# CC2756 register map
File version: 1.0
CPU: CM4 r0p4, little endian, no MPU, no FPU, VTOR, 3 interrupt priority bits
Registers are 32-bit, read-write, reset 0x0 unless marked. A register's access mark holds for its fields unless they carry their own. Offsets are from the block's base; [hi:lo] are bit positions; {n}, {i} and the like mark numbered series; 'fields as' and 'values as' point back to an identical list.

## LRFDRFE32 (part 1 of 2)
Base 0x40083400
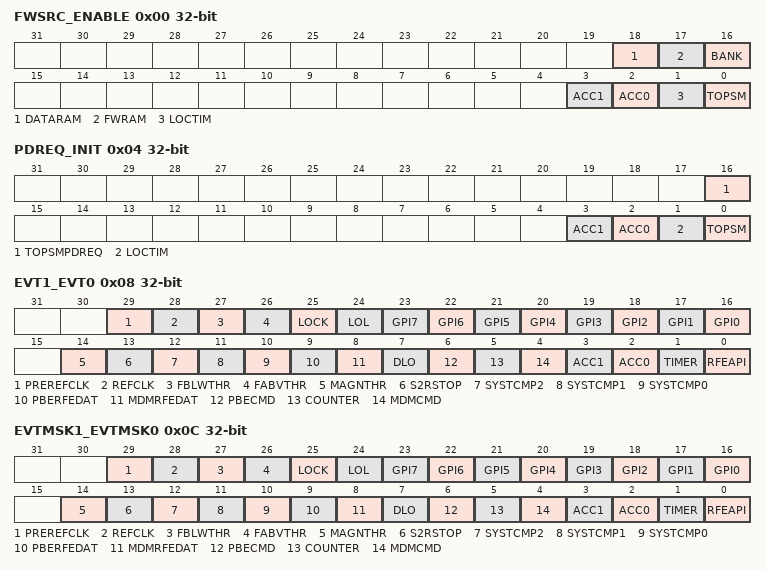
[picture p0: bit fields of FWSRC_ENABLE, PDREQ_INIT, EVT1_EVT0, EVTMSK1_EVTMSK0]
0x00 FWSRC_ENABLE — Internal. Only to be used through TI provided API.
  [18] DATARAM — Internal. Only to be used through TI provided API.
    1=S2RRAM (Internal. Only to be used through TI provided API.); 0=RFERAM (Internal. Only to be used through TI provided API.)
  [17] FWRAM — Internal. Only to be used through TI provided API.
    values as DATARAM
  [16] BANK — Internal. Only to be used through TI provided API.
    1=ONE (Internal. Only to be used through TI provided API.); 0=ZERO (Internal. Only to be used through TI provided API.)
  [3] ACC1 — Internal. Only to be used through TI provided API.
    1=EN (Internal. Only to be used through TI provided API.); 0=DIS (Internal. Only to be used through TI provided API.)
  [2] ACC0 — Internal. Only to be used through TI provided API.
    values as ACC1
  [1] LOCTIM — Internal. Only to be used through TI provided API.
    values as ACC1
  [0] TOPSM — Internal. Only to be used through TI provided API.
    values as ACC1
0x04 PDREQ_INIT wo — Internal. Only to be used through TI provided API.
  [16] TOPSMPDREQ — Internal. Only to be used through TI provided API.
    values as FWSRC_ENABLE.BANK
  [3] ACC1 — Internal. Only to be used through TI provided API.
    1=RESET (Internal. Only to be used through TI provided API.); 0=NO_EFFECT (Internal. Only to be used through TI provided API.)
  [2] ACC0 — Internal. Only to be used through TI provided API.
    values as ACC1
  [1] LOCTIM — Internal. Only to be used through TI provided API.
    values as ACC1
  [0] TOPSM — Internal. Only to be used through TI provided API.
    values as ACC1
0x08 EVT1_EVT0 ro — Internal. Only to be used through TI provided API.
  [all] fields
    values as FWSRC_ENABLE.BANK
  [29] PREREFCLK — Internal. Only to be used through TI provided API.
  [28] REFCLK — Internal. Only to be used through TI provided API.
  [27] FBLWTHR — Internal. Only to be used through TI provided API.
  [26] FABVTHR — Internal. Only to be used through TI provided API.
  [25] LOCK — Internal. Only to be used through TI provided API.
  [24] LOL — Internal. Only to be used through TI provided API.
  [n+16] GPI{n} (n=0..7) — Internal. Only to be used through TI provided API.
  [14] MAGNTHR — Internal. Only to be used through TI provided API.
  [13] S2RSTOP — Internal. Only to be used through TI provided API.
  [12] SYSTCMP2 — Internal. Only to be used through TI provided API.
  [11] SYSTCMP1 — Internal. Only to be used through TI provided API.
  [10] SYSTCMP0 — Internal. Only to be used through TI provided API.
  [9] PBERFEDAT — Internal. Only to be used through TI provided API.
  [8] MDMRFEDAT — Internal. Only to be used through TI provided API.
  [7] DLO — Internal. Only to be used through TI provided API.
  [6] PBECMD — Internal. Only to be used through TI provided API.
  [5] COUNTER — Internal. Only to be used through TI provided API.
  [4] MDMCMD — Internal. Only to be used through TI provided API.
  [3] ACC1 — Internal. Only to be used through TI provided API.
  [2] ACC0 — Internal. Only to be used through TI provided API.
  [1] TIMER — Internal. Only to be used through TI provided API.
  [0] RFEAPI — Internal. Only to be used through TI provided API.
0x0C EVTMSK1_EVTMSK0 — Internal. Only to be used through TI provided API.
  [all] fields
    values as FWSRC_ENABLE.ACC1
  [29] PREREFCLK — Internal. Only to be used through TI provided API.
  [28] REFCLK — Internal. Only to be used through TI provided API.
  [27] FBLWTHR — Internal. Only to be used through TI provided API.
  [26] FABVTHR — Internal. Only to be used through TI provided API.
  [25] LOCK — Internal. Only to be used through TI provided API.
  [24] LOL — Internal. Only to be used through TI provided API.
  [n+16] GPI{n} (n=0..7) — Internal. Only to be used through TI provided API.
  [14] MAGNTHR — Internal. Only to be used through TI provided API.
  [13] S2RSTOP — Internal. Only to be used through TI provided API.
  [12] SYSTCMP2 — Internal. Only to be used through TI provided API.
  [11] SYSTCMP1 — Internal. Only to be used through TI provided API.
  [10] SYSTCMP0 — Internal. Only to be used through TI provided API.
  [9] PBERFEDAT — Internal. Only to be used through TI provided API.
  [8] MDMRFEDAT — Internal. Only to be used through TI provided API.
  [7] DLO — Internal. Only to be used through TI provided API.
  [6] PBECMD — Internal. Only to be used through TI provided API.
  [5] COUNTER — Internal. Only to be used through TI provided API.
  [4] MDMCMD — Internal. Only to be used through TI provided API.
  [3] ACC1 — Internal. Only to be used through TI provided API.
  [2] ACC0 — Internal. Only to be used through TI provided API.
  [1] TIMER — Internal. Only to be used through TI provided API.
  [0] RFEAPI — Internal. Only to be used through TI provided API.
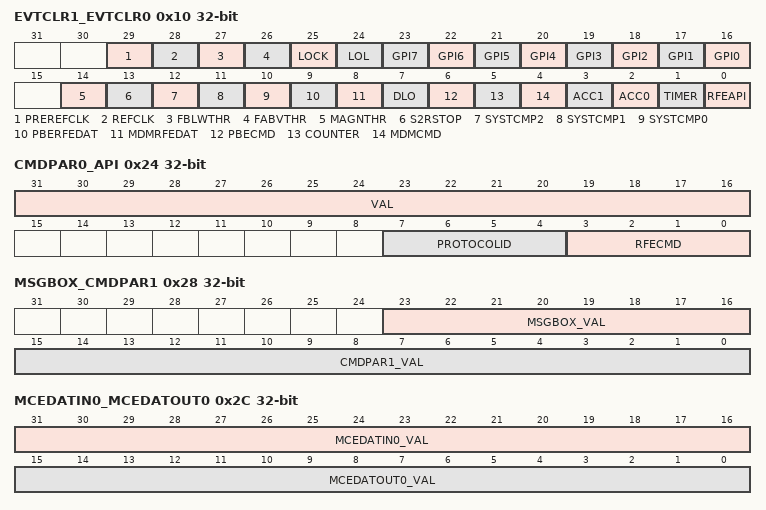
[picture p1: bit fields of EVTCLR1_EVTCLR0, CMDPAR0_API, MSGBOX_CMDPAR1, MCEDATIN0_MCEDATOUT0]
0x10 EVTCLR1_EVTCLR0 wo — Internal. Only to be used through TI provided API.
  fields as EVT1_EVT0
0x14 HFXTSTAT ro — Internal. Only to be used through TI provided API.
  [0] STAT
    1=QUAL (Internal. Only to be used through TI provided API.); 0=NONQUAL (Internal. Only to be used through TI provided API.)
0x18 RFSTATE — Internal. Only to be used through TI provided API.
  [3:0] VAL
    3=RX (Internal. Only to be used through TI provided API.); 2=TX (Internal. Only to be used through TI provided API.); 1=SYNTH (Internal. Only to be used through TI provided API.); 0=IDLE (Internal. Only to be used through TI provided API.)
0x1C SPIN ro reset 0xFF — Internal. Only to be used through TI provided API.
  [7:0] OPT
    255=ALLONES (Internal. Only to be used through TI provided API.); 0=ALLZEROS (Internal. Only to be used through TI provided API.)
0x24 CMDPAR0_API ro — Internal. Only to be used through TI provided API.
  [31:16] VAL — Internal. Only to be used through TI provided API.
    0xFFFF=ALLONES (Internal. Only to be used through TI provided API.); 0=ALLZEROS (Internal. Only to be used through TI provided API.)
  [7:4] PROTOCOLID — Internal. Only to be used through TI provided API.
    15=ALLONES (Internal. Only to be used through TI provided API.); 0=ALLZEROS (Internal. Only to be used through TI provided API.)
  [3:0] RFECMD — Internal. Only to be used through TI provided API.
    values as PROTOCOLID
0x28 MSGBOX_CMDPAR1 ro — Internal. Only to be used through TI provided API.
  [23:16] MSGBOX_VAL — Internal. Only to be used through TI provided API.
    values as SPIN.OPT
  [15:0] CMDPAR1_VAL — Internal. Only to be used through TI provided API.
    values as CMDPAR0_API.VAL
0x2C MCEDATIN0_MCEDATOUT0 — Internal. Only to be used through TI provided API.
  [31:16] MCEDATIN0_VAL ro — Internal. Only to be used through TI provided API.
    values as CMDPAR0_API.VAL
  [15:0] MCEDATOUT0_VAL — Internal. Only to be used through TI provided API.
    values as CMDPAR0_API.VAL
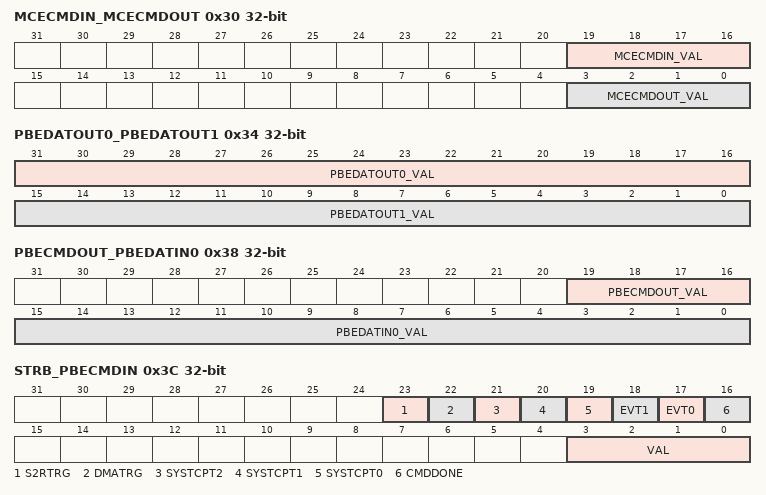
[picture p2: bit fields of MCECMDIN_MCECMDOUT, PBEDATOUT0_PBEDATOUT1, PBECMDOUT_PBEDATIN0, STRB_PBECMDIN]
0x30 MCECMDIN_MCECMDOUT — Internal. Only to be used through TI provided API.
  [19:16] MCECMDIN_VAL ro — Internal. Only to be used through TI provided API.
    values as CMDPAR0_API.PROTOCOLID
  [3:0] MCECMDOUT_VAL — Internal. Only to be used through TI provided API.
    values as CMDPAR0_API.PROTOCOLID
0x34 PBEDATOUT0_PBEDATOUT1 — Internal. Only to be used through TI provided API.
  [31:16] PBEDATOUT0_VAL — Internal. Only to be used through TI provided API.
    values as CMDPAR0_API.VAL
  [15:0] PBEDATOUT1_VAL — Internal. Only to be used through TI provided API.
    values as CMDPAR0_API.VAL
0x38 PBECMDOUT_PBEDATIN0 ro — Internal. Only to be used through TI provided API.
  [19:16] PBECMDOUT_VAL — Internal. Only to be used through TI provided API.
    values as CMDPAR0_API.PROTOCOLID
  [15:0] PBEDATIN0_VAL — Internal. Only to be used through TI provided API.
    values as CMDPAR0_API.VAL
0x3C STRB_PBECMDIN ro — Internal. Only to be used through TI provided API.
  [23] S2RTRG wo — Internal. Only to be used through TI provided API.
    values as FWSRC_ENABLE.BANK
  [22] DMATRG wo — Internal. Only to be used through TI provided API.
    values as FWSRC_ENABLE.BANK
  [21] SYSTCPT2 wo — Internal. Only to be used through TI provided API.
    values as FWSRC_ENABLE.BANK
  [20] SYSTCPT1 wo — Internal. Only to be used through TI provided API.
    values as FWSRC_ENABLE.BANK
  [19] SYSTCPT0 wo — Internal. Only to be used through TI provided API.
    values as FWSRC_ENABLE.BANK
  [18] EVT1 wo — Internal. Only to be used through TI provided API.
    values as FWSRC_ENABLE.BANK
  [17] EVT0 wo — Internal. Only to be used through TI provided API.
    values as FWSRC_ENABLE.BANK
  [16] CMDDONE wo — Internal. Only to be used through TI provided API.
    1=YES (Internal. Only to be used through TI provided API.); 0=NO (Internal. Only to be used through TI provided API.)
  [3:0] VAL — Internal. Only to be used through TI provided API.
    values as CMDPAR0_API.PROTOCOLID
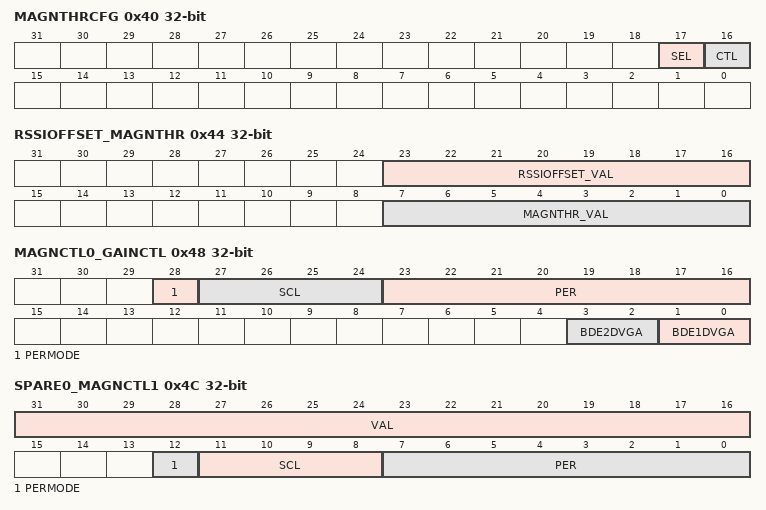
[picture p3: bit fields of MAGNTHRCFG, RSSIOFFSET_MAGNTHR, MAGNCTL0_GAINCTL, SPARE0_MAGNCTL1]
0x40 MAGNTHRCFG — Internal. Only to be used through TI provided API.
  [17] SEL — Internal. Only to be used through TI provided API.
    1=MAGNACC1 (Internal. Only to be used through TI provided API.); 0=MAGNACC0 (Internal. Only to be used through TI provided API.)
  [16] CTL — Internal. Only to be used through TI provided API.
    values as FWSRC_ENABLE.ACC1
0x44 RSSIOFFSET_MAGNTHR — Internal. Only to be used through TI provided API.
  [23:16] RSSIOFFSET_VAL — Internal. Only to be used through TI provided API.
    values as SPIN.OPT
  [7:0] MAGNTHR_VAL — Internal. Only to be used through TI provided API.
    values as SPIN.OPT
0x48 MAGNCTL0_GAINCTL — Internal. Only to be used through TI provided API.
  [28] PERMODE — Internal. Only to be used through TI provided API.
    1=PERIODIC (Internal. Only to be used through TI provided API.); 0=ONESHOT (Internal. Only to be used through TI provided API.)
  [27:24] SCL — Internal. Only to be used through TI provided API.
    8=DIV256 (Internal. Only to be used through TI provided API.); 7=DIV128 (Internal. Only to be used through TI provided API.); 6=DIV64 (Internal. Only to be used through TI provided API.); 5=DIV32 (Internal. Only to be used through TI provided API.); 4=DIV16 (Internal. Only to be used through TI provided API.); 3=DIV8 (Internal. Only to be used through TI provided API.); 2=DIV4 (Internal. Only to be used through TI provided API.); 1=DIV2 (Internal. Only to be used through TI provided API.); 0=DIV1 (Internal. Only to be used through TI provided API.)
  [23:16] PER — Internal. Only to be used through TI provided API.
    values as SPIN.OPT
  [3:2] BDE2DVGA — Internal. Only to be used through TI provided API.
    3=GAIN8 (Internal. Only to be used through TI provided API.); 2=GAIN4 (Internal. Only to be used through TI provided API.); 1=GAIN2 (Internal. Only to be used through TI provided API.); 0=GAIN1 (Internal. Only to be used through TI provided API.)
  [1:0] BDE1DVGA — Internal. Only to be used through TI provided API.
    values as BDE2DVGA
0x4C SPARE0_MAGNCTL1 — Internal. Only to be used through TI provided API.
  [31:16] VAL — Internal. Only to be used through TI provided API.
    values as CMDPAR0_API.VAL
  [12] PERMODE — Internal. Only to be used through TI provided API.
    values as MAGNCTL0_GAINCTL.PERMODE
  [11:8] SCL — Internal. Only to be used through TI provided API.
    values as MAGNCTL0_GAINCTL.SCL
  [7:0] PER — Internal. Only to be used through TI provided API.
    values as SPIN.OPT
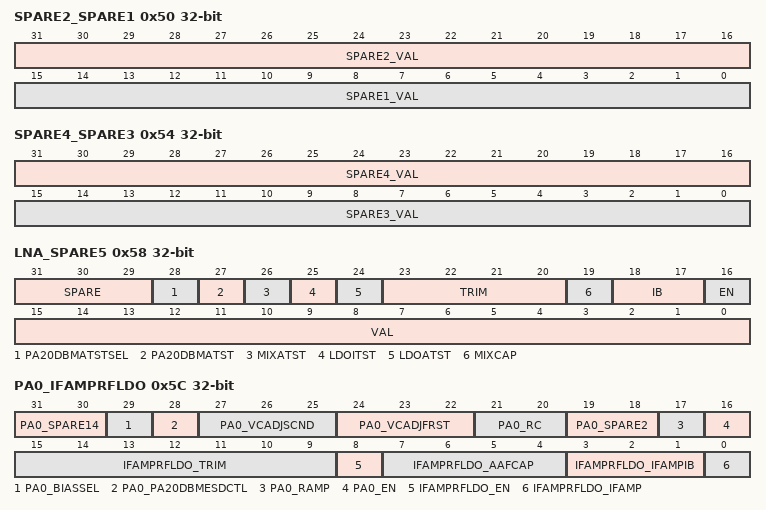
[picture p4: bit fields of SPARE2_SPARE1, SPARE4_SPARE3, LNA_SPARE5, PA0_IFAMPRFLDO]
0x50 SPARE2_SPARE1 — Internal. Only to be used through TI provided API.
  [31:16] SPARE2_VAL — Internal. Only to be used through TI provided API.
    values as CMDPAR0_API.VAL
  [15:0] SPARE1_VAL — Internal. Only to be used through TI provided API.
    values as CMDPAR0_API.VAL
0x54 SPARE4_SPARE3 — Internal. Only to be used through TI provided API.
  [31:16] SPARE4_VAL — Internal. Only to be used through TI provided API.
    values as CMDPAR0_API.VAL
  [15:0] SPARE3_VAL — Internal. Only to be used through TI provided API.
    values as CMDPAR0_API.VAL
0x58 LNA_SPARE5 — Internal. Only to be used through TI provided API.
  [31:29] SPARE — Internal. Only to be used through TI provided API.
    values as FWSRC_ENABLE.ACC1
  [28] PA20DBMATSTSEL — Internal. Only to be used through TI provided API.
    1=SECOND (Internal. Only to be used through TI provided API.); 0=FIRST (Internal. Only to be used through TI provided API.)
  [27] PA20DBMATST — Internal. Only to be used through TI provided API.
    values as FWSRC_ENABLE.ACC1
  [26] MIXATST — Internal. Only to be used through TI provided API.
    values as FWSRC_ENABLE.ACC1
  [25] LDOITST — Internal. Only to be used through TI provided API.
    values as FWSRC_ENABLE.ACC1
  [24] LDOATST — Internal. Only to be used through TI provided API.
    values as FWSRC_ENABLE.ACC1
  [23:20] TRIM — Internal. Only to be used through TI provided API.
    15=ONES (Internal. Only to be used through TI provided API.); 0=ZEROS (Internal. Only to be used through TI provided API.)
  [19] MIXCAP — Internal. Only to be used through TI provided API.
    values as FWSRC_ENABLE.ACC1
  [18:17] IB — Internal. Only to be used through TI provided API.
    3=MAX (Internal. Only to be used through TI provided API.); 0=MIN (Internal. Only to be used through TI provided API.)
  [16] EN — Internal. Only to be used through TI provided API.
    1=ON (Internal. Only to be used through TI provided API.); 0=OFF (Internal. Only to be used through TI provided API.)
  [15:0] VAL — Internal. Only to be used through TI provided API.
    values as CMDPAR0_API.VAL
0x5C PA0_IFAMPRFLDO — Internal. Only to be used through TI provided API.
  [31:30] PA0_SPARE14 — Internal. Only to be used through TI provided API.
    values as LNA_SPARE5.IB
  [29] PA0_BIASSEL — Internal. Only to be used through TI provided API.
    values as FWSRC_ENABLE.BANK
  [28] PA0_PA20DBMESDCTL — Internal. Only to be used through TI provided API.
    values as FWSRC_ENABLE.BANK
  [27:25] PA0_VCADJSCND — Internal. Only to be used through TI provided API.
    7=MAX (Internal. Only to be used through TI provided API.); 0=MIN (Internal. Only to be used through TI provided API.)
  [24:22] PA0_VCADJFRST — Internal. Only to be used through TI provided API.
    values as PA0_VCADJSCND
  [21:20] PA0_RC — Internal. Only to be used through TI provided API.
    values as LNA_SPARE5.IB
  [19:18] PA0_SPARE2 — Internal. Only to be used through TI provided API.
    values as LNA_SPARE5.IB
  [17] PA0_RAMP — Internal. Only to be used through TI provided API.
    1=UP (Internal. Only to be used through TI provided API.); 0=DOWN (Internal. Only to be used through TI provided API.)
  [16] PA0_EN — Internal. Only to be used through TI provided API.
    values as FWSRC_ENABLE.ACC1
  [15:9] IFAMPRFLDO_TRIM — Internal. Only to be used through TI provided API.
    127=BYPASS (Internal. Only to be used through TI provided API.); 126=MAX (Internal. Only to be used through TI provided API.); 0=MIN (Internal. Only to be used through TI provided API.)
  [8] IFAMPRFLDO_EN — Internal. Only to be used through TI provided API.
    values as FWSRC_ENABLE.ACC1
  [7:4] IFAMPRFLDO_AAFCAP — Internal. Only to be used through TI provided API.
    15=MAX (Internal. Only to be used through TI provided API.); 0=MIN (Internal. Only to be used through TI provided API.)
  [3:1] IFAMPRFLDO_IFAMPIB — Internal. Only to be used through TI provided API.
    values as PA0_VCADJSCND
  [0] IFAMPRFLDO_IFAMP — Internal. Only to be used through TI provided API.
    values as FWSRC_ENABLE.ACC1
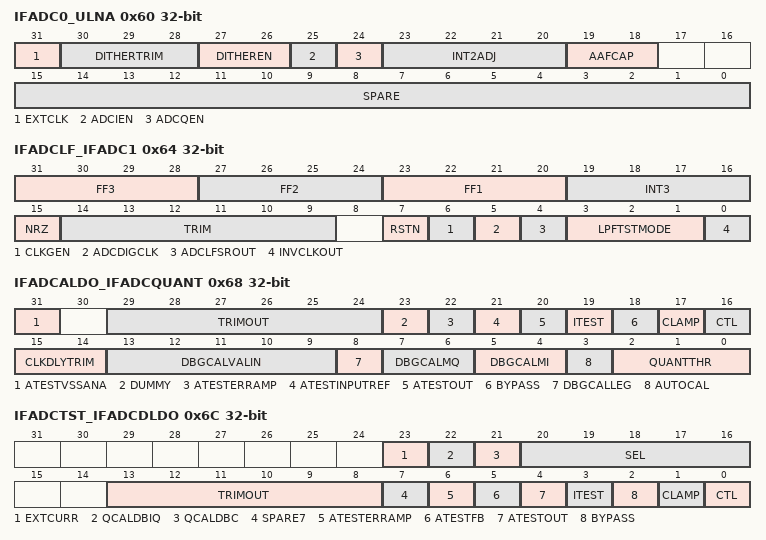
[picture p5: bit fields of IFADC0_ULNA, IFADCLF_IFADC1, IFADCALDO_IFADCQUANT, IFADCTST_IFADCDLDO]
0x60 IFADC0_ULNA — Internal. Only to be used through TI provided API.
  [31] EXTCLK — Internal. Only to be used through TI provided API.
    values as FWSRC_ENABLE.ACC1
  [30:28] DITHERTRIM — Internal. Only to be used through TI provided API.
    7=ONES (Internal. Only to be used through TI provided API.); 0=ZEROS (Internal. Only to be used through TI provided API.)
  [27:26] DITHEREN — Internal. Only to be used through TI provided API.
    3=ENG (Internal. Only to be used through TI provided API.); 2=ENSD (Internal. Only to be used through TI provided API.); 1=ENS (Internal. Only to be used through TI provided API.); 0=DIS (Internal. Only to be used through TI provided API.)
  [25] ADCIEN — Internal. Only to be used through TI provided API.
    values as FWSRC_ENABLE.ACC1
  [24] ADCQEN — Internal. Only to be used through TI provided API.
    values as FWSRC_ENABLE.ACC1
  [23:20] INT2ADJ — Internal. Only to be used through TI provided API.
    values as LNA_SPARE5.TRIM
  [19:18] AAFCAP — Internal. Only to be used through TI provided API.
    values as DITHEREN
  [15:0] SPARE — Internal. Only to be used through TI provided API.
    values as CMDPAR0_API.VAL
0x64 IFADCLF_IFADC1 — Internal. Only to be used through TI provided API.
  [31:28] FF3 — Internal. Only to be used through TI provided API.
    values as LNA_SPARE5.TRIM
  [27:24] FF2 — Internal. Only to be used through TI provided API.
    values as LNA_SPARE5.TRIM
  [23:20] FF1 — Internal. Only to be used through TI provided API.
    values as LNA_SPARE5.TRIM
  [19:16] INT3 — Internal. Only to be used through TI provided API.
    values as LNA_SPARE5.TRIM
  [15] NRZ — Internal. Only to be used through TI provided API.
    values as FWSRC_ENABLE.ACC1
  [14:9] TRIM — Internal. Only to be used through TI provided API.
    63=ONES (Internal. Only to be used through TI provided API.); 0=ZEROS (Internal. Only to be used through TI provided API.)
  [7] RSTN — Internal. Only to be used through TI provided API.
    1=DIS (Internal. Only to be used through TI provided API.); 0=EN (Internal. Only to be used through TI provided API.)
  [6] CLKGEN — Internal. Only to be used through TI provided API.
    values as FWSRC_ENABLE.ACC1
  [5] ADCDIGCLK — Internal. Only to be used through TI provided API.
    values as FWSRC_ENABLE.ACC1
  [4] ADCLFSROUT — Internal. Only to be used through TI provided API.
    values as FWSRC_ENABLE.ACC1
  [3:1] LPFTSTMODE — Internal. Only to be used through TI provided API.
    values as FWSRC_ENABLE.ACC1
  [0] INVCLKOUT — Internal. Only to be used through TI provided API.
    values as FWSRC_ENABLE.ACC1
0x68 IFADCALDO_IFADCQUANT — Internal. Only to be used through TI provided API.
  [31] ATESTVSSANA — Internal. Only to be used through TI provided API.
    values as FWSRC_ENABLE.ACC1
  [29:24] TRIMOUT — Internal. Only to be used through TI provided API.
    values as IFADCLF_IFADC1.TRIM
  [23] DUMMY — Internal. Only to be used through TI provided API.
    1=DISN (Internal. Only to be used through TI provided API.); 0=ENN (Internal. Only to be used through TI provided API.)
  [22] ATESTERRAMP — Internal. Only to be used through TI provided API.
    values as FWSRC_ENABLE.ACC1
  [21] ATESTINPUTREF — Internal. Only to be used through TI provided API.
    values as FWSRC_ENABLE.ACC1
  [20] ATESTOUT — Internal. Only to be used through TI provided API.
    values as FWSRC_ENABLE.ACC1
  [19] ITEST — Internal. Only to be used through TI provided API.
    values as FWSRC_ENABLE.ACC1
  [18] BYPASS — Internal. Only to be used through TI provided API.
    values as FWSRC_ENABLE.ACC1
  [17] CLAMP — Internal. Only to be used through TI provided API.
    values as FWSRC_ENABLE.ACC1
  [16] CTL — Internal. Only to be used through TI provided API.
    values as FWSRC_ENABLE.ACC1
  [15:14] CLKDLYTRIM — Internal. Only to be used through TI provided API.
    3=ONES (Internal. Only to be used through TI provided API.); 0=ZEROS (Internal. Only to be used through TI provided API.)
  [13:9] DBGCALVALIN — Internal. Only to be used through TI provided API.
    31=ONES (Internal. Only to be used through TI provided API.); 0=ZEROS (Internal. Only to be used through TI provided API.)
  [8] DBGCALLEG — Internal. Only to be used through TI provided API.
    1=NEG (Internal. Only to be used through TI provided API.); 0=POS (Internal. Only to be used through TI provided API.)
  [7:6] DBGCALMQ — Internal. Only to be used through TI provided API.
    3=DBGCAL_QMODB (Internal. Only to be used through TI provided API.); 2=DBGCAL_QMODP (Internal. Only to be used through TI provided API.); 1=DBGCAL_QMODN (Internal. Only to be used through TI provided API.); 0=DBGCAL_QMODZ (Internal. Only to be used through TI provided API.)
  [5:4] DBGCALMI — Internal. Only to be used through TI provided API.
    3=DBGCAL_IMODB (Internal. Only to be used through TI provided API.); 2=DBGCAL_IMODP (Internal. Only to be used through TI provided API.); 1=DBGCAL_IMODN (Internal. Only to be used through TI provided API.); 0=DBGCAL_IMODZ (Internal. Only to be used through TI provided API.)
  [3] AUTOCAL — Internal. Only to be used through TI provided API.
    values as FWSRC_ENABLE.ACC1
  [2:0] QUANTTHR — Internal. Only to be used through TI provided API.
    values as IFADC0_ULNA.DITHERTRIM
0x6C IFADCTST_IFADCDLDO — Internal. Only to be used through TI provided API.
  [23] EXTCURR — Internal. Only to be used through TI provided API.
    values as FWSRC_ENABLE.ACC1
  [22] QCALDBIQ — Internal. Only to be used through TI provided API.
    1=COMP1 (Internal. Only to be used through TI provided API.); 0=COMP0 (Internal. Only to be used through TI provided API.)
  [21] QCALDBC — Internal. Only to be used through TI provided API.
    values as QCALDBIQ
  [20:16] SEL — Internal. Only to be used through TI provided API.
    31=EXTCLKN1 (Internal. Only to be used through TI provided API.); 0=NONE (Internal. Only to be used through TI provided API.)
  [13:8] TRIMOUT — Internal. Only to be used through TI provided API.
    values as IFADCLF_IFADC1.TRIM
  [7] SPARE7 — Internal. Only to be used through TI provided API.
    1=One (Internal. Only to be used through TI provided API.); 0=ZERO (Internal. Only to be used through TI provided API.)
  [6] ATESTERRAMP — Internal. Only to be used through TI provided API.
    values as FWSRC_ENABLE.ACC1
  [5] ATESTFB — Internal. Only to be used through TI provided API.
    values as FWSRC_ENABLE.ACC1
  [4] ATESTOUT — Internal. Only to be used through TI provided API.
    values as FWSRC_ENABLE.ACC1
  [3] ITEST — Internal. Only to be used through TI provided API.
    values as FWSRC_ENABLE.ACC1
  [2] BYPASS — Internal. Only to be used through TI provided API.
    values as FWSRC_ENABLE.ACC1
  [1] CLAMP — Internal. Only to be used through TI provided API.
    values as FWSRC_ENABLE.ACC1
  [0] CTL — Internal. Only to be used through TI provided API.
    values as FWSRC_ENABLE.ACC1
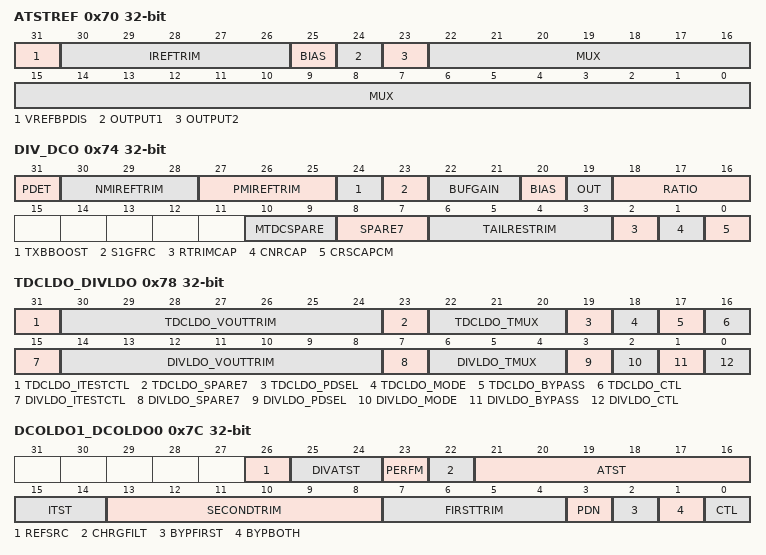
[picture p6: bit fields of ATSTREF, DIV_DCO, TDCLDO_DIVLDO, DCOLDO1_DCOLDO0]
0x70 ATSTREF — Internal. Only to be used through TI provided API.
  [31] VREFBPDIS — Internal. Only to be used through TI provided API.
    1=BPDIS (Internal. Only to be used through TI provided API.); 0=BPEN (Internal. Only to be used through TI provided API.)
  [30:26] IREFTRIM — Internal. Only to be used through TI provided API.
    values as IFADCALDO_IFADCQUANT.DBGCALVALIN
  [25] BIAS — Internal. Only to be used through TI provided API.
    values as FWSRC_ENABLE.ACC1
  [24] OUTPUT1 — Internal. Only to be used through TI provided API.
    values as FWSRC_ENABLE.ACC1
  [23] OUTPUT2 — Internal. Only to be used through TI provided API.
    values as FWSRC_ENABLE.ACC1
  [22:0] MUX — Internal. Only to be used through TI provided API.
    0x8000=IFADC_ATB (Internal. Only to be used through TI provided API.); 0x4000=LDO_VTEST (Internal. Only to be used through TI provided API.); 0x2000=LDO_ITEST (Internal. Only to be used through TI provided API.); 0x800=PA_PEAK_OUTN (Internal. Only to be used through TI provided API.); 0x400=PA_PEAK_OUTP (Internal. Only to be used through TI provided API.); 0x200=MIX_OUTQN (Internal. Only to be used through TI provided API.); 0x100=MIX_OUTQP (Internal. Only to be used through TI provided API.); 128=MIX_OUTIN (Internal. Only to be used through TI provided API.); 64=MIX_OUTIP (Internal. Only to be used through TI provided API.); 32=FE_OUTIN_2 (Internal. Only to be used through TI provided API.); 16=FE_OUTIP_2 (Internal. Only to be used through TI provided API.); 8=FE_OUTQN (Internal. Only to be used through TI provided API.); 4=FE_OUTQP (Internal. Only to be used through TI provided API.); 2=FE_OUTIN (Internal. Only to be used through TI provided API.); 1=FE_OUTIP (Internal. Only to be used through TI provided API.); 0=DIS (Internal. Only to be used through TI provided API.)
0x74 DIV_DCO — Internal. Only to be used through TI provided API.
  [31] PDET — Internal. Only to be used through TI provided API.
    values as FWSRC_ENABLE.ACC1
  [30:28] NMIREFTRIM — Internal. Only to be used through TI provided API.
    7=ALLONES (Internal. Only to be used through TI provided API.); 0=ALLZEROS (Internal. Only to be used through TI provided API.)
  [27:25] PMIREFTRIM — Internal. Only to be used through TI provided API.
    values as NMIREFTRIM
  [24] TXBBOOST — Internal. Only to be used through TI provided API.
    1=INCREASED (Internal. Only to be used through TI provided API.); 0=DEFAULT (Internal. Only to be used through TI provided API.)
  [23] S1GFRC — Internal. Only to be used through TI provided API.
    values as FWSRC_ENABLE.ACC1
  [22:21] BUFGAIN — Internal. Only to be used through TI provided API.
    3=_60_PST (Internal. Only to be used through TI provided API.); 2=DONT_USE (Internal. Only to be used through TI provided API.); 1=_80_PST (Internal. Only to be used through TI provided API.); 0=MAX (Internal. Only to be used through TI provided API.)
  [20] BIAS — Internal. Only to be used through TI provided API.
    1=DEFAULT (Internal. Only to be used through TI provided API.); 0=ALTERNATIVE (Internal. Only to be used through TI provided API.)
  [19] OUT — Internal. Only to be used through TI provided API.
    1=FE_2G4 (Internal. Only to be used through TI provided API.); 0=FE_S1G (Internal. Only to be used through TI provided API.)
  [18:16] RATIO — Internal. Only to be used through TI provided API.
    7=DIV30 (Internal. Only to be used through TI provided API.); 6=DIV15 (Internal. Only to be used through TI provided API.); 5=DIV10 (Internal. Only to be used through TI provided API.); 4=DIV5 (Internal. Only to be used through TI provided API.); 3=DIV12 (Internal. Only to be used through TI provided API.); 2=DIV6 (Internal. Only to be used through TI provided API.); 1=DIV4 (Internal. Only to be used through TI provided API.); 0=DIV2 (Internal. Only to be used through TI provided API.)
  [10:9] MTDCSPARE — Internal. Only to be used through TI provided API.
    values as IFADCLF_IFADC1.RSTN
  [8:7] SPARE7 — Internal. Only to be used through TI provided API.
    values as FWSRC_ENABLE.BANK
  [6:3] TAILRESTRIM — Internal. Only to be used through TI provided API.
    values as CMDPAR0_API.PROTOCOLID
  [2] RTRIMCAP — Internal. Only to be used through TI provided API.
    values as FWSRC_ENABLE.ACC1
  [1] CNRCAP — Internal. Only to be used through TI provided API.
    1=_50MHZ (Internal. Only to be used through TI provided API.); 0=DEFAULT (Internal. Only to be used through TI provided API.)
  [0] CRSCAPCM — Internal. Only to be used through TI provided API.
    1=REDUCED (Internal. Only to be used through TI provided API.); 0=DEFAULT (Internal. Only to be used through TI provided API.)
0x78 TDCLDO_DIVLDO — Internal. Only to be used through TI provided API.
  [31] TDCLDO_ITESTCTL — Internal. Only to be used through TI provided API.
    values as FWSRC_ENABLE.ACC1
  [30:24] TDCLDO_VOUTTRIM — Internal. Only to be used through TI provided API.
    127=ONES (Internal. Only to be used through TI provided API.); 0=ZEROS (Internal. Only to be used through TI provided API.)
  [23] TDCLDO_SPARE7 — Internal. Only to be used through TI provided API.
    values as IFADCTST_IFADCDLDO.SPARE7
  [22:20] TDCLDO_TMUX — Internal. Only to be used through TI provided API.
    4=VSSR (Internal. Only to be used through TI provided API.); 2=LDO_OUT (Internal. Only to be used through TI provided API.); 1=VDDR (Internal. Only to be used through TI provided API.); 0=OFF (Internal. Only to be used through TI provided API.)
  [19] TDCLDO_PDSEL — Internal. Only to be used through TI provided API.
    1=DIODE (Internal. Only to be used through TI provided API.); 0=R (Internal. Only to be used through TI provided API.)
  [18] TDCLDO_MODE — Internal. Only to be used through TI provided API.
    1=FAST (Internal. Only to be used through TI provided API.); 0=NORM (Internal. Only to be used through TI provided API.)
  [17] TDCLDO_BYPASS — Internal. Only to be used through TI provided API.
    values as FWSRC_ENABLE.ACC1
  [16] TDCLDO_CTL — Internal. Only to be used through TI provided API.
    values as FWSRC_ENABLE.ACC1
  [15] DIVLDO_ITESTCTL — Internal. Only to be used through TI provided API.
    values as FWSRC_ENABLE.ACC1
  [14:8] DIVLDO_VOUTTRIM — Internal. Only to be used through TI provided API.
    values as TDCLDO_VOUTTRIM
  [7] DIVLDO_SPARE7 — Internal. Only to be used through TI provided API.
    1=ONE (Internal. Only to be used through TI provided API.); 0=Zero (Internal. Only to be used through TI provided API.)
  [6:4] DIVLDO_TMUX — Internal. Only to be used through TI provided API.
    values as TDCLDO_TMUX
  [3] DIVLDO_PDSEL — Internal. Only to be used through TI provided API.
    values as TDCLDO_PDSEL
  [2] DIVLDO_MODE — Internal. Only to be used through TI provided API.
    values as TDCLDO_MODE
  [1] DIVLDO_BYPASS — Internal. Only to be used through TI provided API.
    values as FWSRC_ENABLE.ACC1
  [0] DIVLDO_CTL — Internal. Only to be used through TI provided API.
    values as FWSRC_ENABLE.ACC1
0x7C DCOLDO1_DCOLDO0 — Internal. Only to be used through TI provided API.
  [26] REFSRC — Internal. Only to be used through TI provided API.
    1=BAW (Internal. Only to be used through TI provided API.); 0=XTAL (Internal. Only to be used through TI provided API.)
  [25:24] DIVATST — Internal. Only to be used through TI provided API.
    values as IFADCALDO_IFADCQUANT.CLKDLYTRIM
  [23] PERFM — Internal. Only to be used through TI provided API.
    values as FWSRC_ENABLE.ACC1
  [22] CHRGFILT — Internal. Only to be used through TI provided API.
    values as FWSRC_ENABLE.ACC1
  [21:16] ATST — Internal. Only to be used through TI provided API.
    32=VSSANA (Internal. Only to be used through TI provided API.); 1=FIRST_OUT (Internal. Only to be used through TI provided API.); 0=LDO_OUT (Internal. Only to be used through TI provided API.)
  [15:14] ITST — Internal. Only to be used through TI provided API.
    3=BOTH (Internal. Only to be used through TI provided API.); 2=SECOND (Internal. Only to be used through TI provided API.); 1=FIRST (Internal. Only to be used through TI provided API.); 0=DIS (Internal. Only to be used through TI provided API.)
  [13:8] SECONDTRIM — Internal. Only to be used through TI provided API.
    values as IFADCLF_IFADC1.TRIM
  [7:4] FIRSTTRIM — Internal. Only to be used through TI provided API.
    values as LNA_SPARE5.TRIM
  [3] PDN — Internal. Only to be used through TI provided API.
    values as FWSRC_ENABLE.ACC1
  [2] BYPFIRST — Internal. Only to be used through TI provided API.
    values as FWSRC_ENABLE.ACC1
  [1] BYPBOTH — Internal. Only to be used through TI provided API.
    values as FWSRC_ENABLE.ACC1
  [0] CTL — Internal. Only to be used through TI provided API.
    values as FWSRC_ENABLE.ACC1
